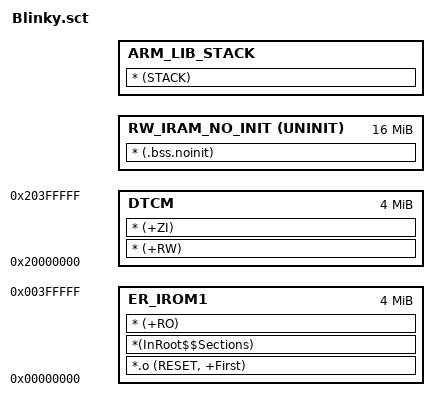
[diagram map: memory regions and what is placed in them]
; *************************************************************
; *** Scatter-Loading Description File generated by uVision ***
; *************************************************************

LR_IROM1 0x00000000 0x00400000  {    ; load region size_region
    ER_IROM1 0x00000000 0x00400000  {  ; load address = execution address
    *.o (RESET, +First)
    *(InRoot$$Sections)
    * (+RO)
    }
    
    DTCM 0x20000000 0x00400000  {  ; RW data
        * (+RW)
        * (+ZI)
    }
    RW_IRAM_NO_INIT +0 UNINIT 0x01000000 {
      * (.bss.noinit)
    }
    ARM_LIB_STACK +0 ALIGN 8   {
        * (STACK)
    }
    
    /*
    RW_IRAM_BSS 0x60000000 PRAM_SIZE {
      * (+ZI)
    }
    RW_IRAM_NO_INIT +0 UNINIT PRAM_SIZE {
      * (.bss.noinit)
    }
    ARM_LIB_HEAP  +0 ALIGN 64 HEAP_SIZE {
        * (HEAP)
    }
    */
}

